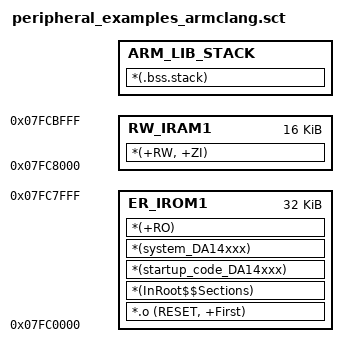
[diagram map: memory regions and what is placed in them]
; *************************************************************
; *** Scatter-Loading Description File generated by uVision ***
; *************************************************************

LR_IROM1 0x07FC0000 0x00008000 {
    ER_IROM1 0x07FC0000 0x00008000 {
        *.o (RESET, +First)
        *(InRoot$$Sections)
        *(startup_code_DA14xxx)
        *(system_DA14xxx)
        *(+RO)
    }

    RW_IRAM1 0x07FC8000 0x00004000 {
        *(+RW, +ZI)
    }

    ARM_LIB_STACK +0 {                  ; reserve region for stack
        *(.bss.stack)
    }
}
